# RA6M2 register map
Vendor: Renesas Electronics Corporation; Series: RA6; File version: 1.1
CPU: CM4 r0p1, little endian, MPU, FPU, VTOR, 4 interrupt priority bits
Registers are 8-bit, read-write, reset 0x0 unless marked. A register's access mark holds for its fields unless they carry their own. Offsets are from the block's base; [hi:lo] are bit positions; {n}, {i} and the like mark numbered series; 'fields as' and 'values as' point back to an identical list.

## GPT32EH0 (part 1 of 2) — General PWM Timer 0 (32-bit Enhanced High Resolution)
Base 0x40078000
Same registers: GPT32EH1 0x40078100, GPT32EH2 0x40078200, GPT32EH3 0x40078300, GPT32E4 0x40078400, GPT32E5 0x40078500, GPT32E6 0x40078600, GPT32E7 0x40078700
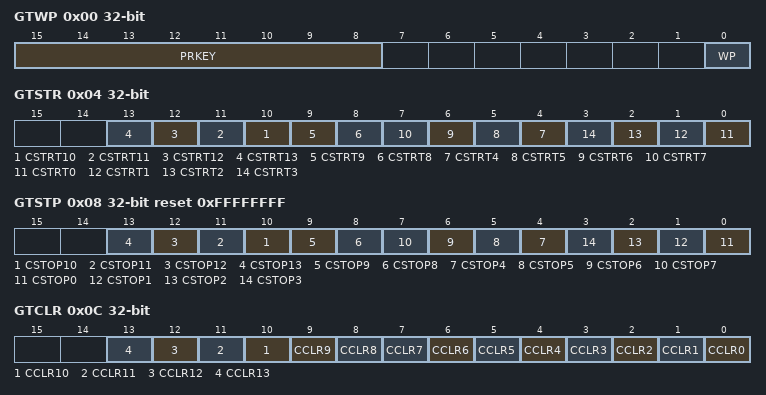
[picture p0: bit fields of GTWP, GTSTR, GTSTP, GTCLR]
0x00 GTWP 32-bit — General PWM Timer Write-Protection Register
  [15:8] PRKEY wo — GTWP Key Code
    165=Written to these bits, the WP bits write is permitted; other=others (The WP bits write is not permitted.)
  [0] WP — Register Write Disable
    0=Enable writes to the register; 1=Disable writes to the register
0x04 GTSTR 32-bit — General PWM Timer Software Start Register
  [n] CSTRT{n} (n=10..13) — Channel {n} GTCNT Count StartRead data shows each channel's counter status (GTCR.CST bit). 0 means counter stop. 1 means counter running.
    0=No effect (write) / counter stop (read); 1=GPT{n+3200}.GTCNT counter starts (write) / Counter running (read)
  [9] CSTRT9 — Channel 9 GTCNT Count StartRead data shows each channel's counter status (GTCR.CST bit). 0 means counter stop. 1 means counter running.
    0=No effect (write) / counter stop (read); 1=GPT329.GTCNT counter starts (write) / Counter running (read)
  [8] CSTRT8 — Channel 8 GTCNT Count StartRead data shows each channel's counter status (GTCR.CST bit). 0 means counter stop. 1 means counter running.
    0=No effect (write) / counter stop (read); 1=GPT328.GTCNT counter starts (write) / Counter running (read)
  [n] CSTRT{n} (n=4..7) — Channel {n} GTCNT Count StartRead data shows each channel's counter status (GTCR.CST bit). 0 means counter stop. 1 means counter running.
    0=No effect (write) / counter stop (read); 1=GPT32E{n}.GTCNT counter starts (write) / Counter running (read)
  [n] CSTRT{n} (n=0..3) — Channel {n} GTCNT Count StartRead data shows each channel's counter status (GTCR.CST bit). 0 means counter stop. 1 means counter running.
    0=No effect (write) / counter stop (read); 1=GPT32EH{n}.GTCNT counter starts (write) / Counter running (read)
0x08 GTSTP 32-bit reset 0xFFFFFFFF — General PWM Timer Software Stop Register
  [n] CSTOP{n} (n=10..13) — Channel {n} GTCNT Count StopRead data shows each channel's counter status (GTCR.CST bit). 0 means counter runnning. 1 means counter stop.
    0=No effect (write) / counter running (read); 1=GPT{n+3200}.GTCNT counter stops (write) / Counter stop (read)
  [9] CSTOP9 — Channel 9 GTCNT Count StopRead data shows each channel's counter status (GTCR.CST bit). 0 means counter runnning. 1 means counter stop.
    0=No effect (write) / counter running (read); 1=GPT329.GTCNT counter stops (write) / Counter stop (read)
  [8] CSTOP8 — Channel 8 GTCNT Count StopRead data shows each channel's counter status (GTCR.CST bit). 0 means counter runnning. 1 means counter stop.
    0=No effect (write) / counter running (read); 1=GPT328.GTCNT counter stops (write) / Counter stop (read)
  [n] CSTOP{n} (n=4..7) — Channel {n} GTCNT Count StopRead data shows each channel's counter status (GTCR.CST bit). 0 means counter runnning. 1 means counter stop.
    0=No effect (write) / counter running (read); 1=GPT32E{n}.GTCNT counter stops (write) / Counter stop (read)
  [n] CSTOP{n} (n=0..3) — Channel {n} GTCNT Count StopRead data shows each channel's counter status (GTCR.CST bit). 0 means counter runnning. 1 means counter stop.
    0=No effect (write) / counter running (read); 1=GPT32EH{n}.GTCNT counter stops (write) / Counter stop (read)
0x0C GTCLR 32-bit wo — General PWM Timer Software Clear Register
  [n] CCLR{n} (n=10..13) — Channel {n} GTCNT Count Clear
    0=No effect; 1=GPT{n+3200}.GTCNT counter clears
  [9] CCLR9 — Channel 9 GTCNT Count Clear
    0=No effect; 1=GPT329.GTCNT counter clears
  [8] CCLR8 — Channel 8 GTCNT Count Clear
    0=No effect; 1=GPT328.GTCNT counter clears
  [n] CCLR{n} (n=4..7) — Channel {n} GTCNT Count Clear
    0=No effect; 1=GPT32E{n}.GTCNT counter clears
  [n] CCLR{n} (n=0..3) — Channel {n} GTCNT Count Clear
    0=No effect; 1=GPT32EH{n}.GTCNT counter clears
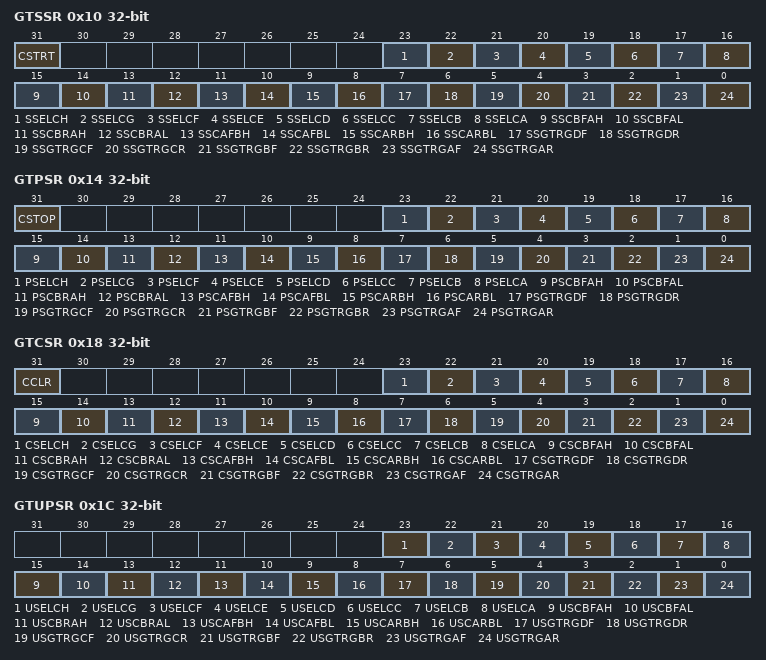
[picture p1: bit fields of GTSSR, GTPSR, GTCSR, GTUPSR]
0x10 GTSSR 32-bit — General PWM Timer Start Source Select Register
  [31] CSTRT — Software Source Counter Start Enable
    0=Disable counter start by the GTSTR register; 1=Enable counter start by the GTSTR register
  [23] SSELCH — ELC_GPTH Event Source Counter Start Enable
    0=Disable counter start on ELC_GPTH input; 1=Enable counter start on ELC_GPTH input
  [22] SSELCG — ELC_GPTG Event Source Counter Start Enable
    0=Disable counter start on ELC_GPTG input; 1=Enable counter start on ELC_GPTG input
  [21] SSELCF — ELC_GPTF Event Source Counter Start Enable
    0=Disable counter start on ELC_GPTF input; 1=Enable counter start on ELC_GPTF input
  [20] SSELCE — ELC_GPTE Event Source Counter Start Enable
    0=Disable counter start on ELC_GPTE input; 1=Enable counter start on ELC_GPTE input
  [19] SSELCD — ELC_GPTD Event Source Counter Start Enable
    0=Disable counter start on ELC_GPTD input; 1=Enable counter start on ELC_GPTD input
  [18] SSELCC — ELC_GPTC Event Source Counter Start Enable
    0=Disable counter start on ELC_GPTC input; 1=Enable counter start on ELC_GPTC input
  [17] SSELCB — ELC_GPTB Event Source Counter Start Enable
    0=Disable counter start on ELC_GPTB input; 1=Enable counter start on ELC_GPTB input
  [16] SSELCA — ELC_GPTA Event Source Counter Start Enable
    0=Disable counter start on ELC_GPTA input; 1=Enable counter start on ELC_GPTA input
  [15] SSCBFAH — GTIOCB Pin Falling Input during GTIOCA Value High Source Counter Start Enable
    0=Disable counter start on the falling edge of GTIOCB input when GTIOCA input is 1; 1=Enable counter start on the falling edge of GTIOCB input when GTIOCA input is 1
  [14] SSCBFAL — GTIOCB Pin Falling Input during GTIOCA Value Low Source Counter Start Enable
    0=Disable counter start on the falling edge of GTIOCB input when GTIOCA input is 0; 1=Enable counter start on the falling edge of GTIOCB input when GTIOCA input is 0
  [13] SSCBRAH — GTIOCB Pin Rising Input during GTIOCA Value High Source Counter Start Enable
    0=Disable counter start on the rising edge of GTIOCB input when GTIOCA input is 1; 1=Enable counter start on the rising edge of GTIOCB input when GTIOCA input is 1
  [12] SSCBRAL — GTIOCB Pin Rising Input during GTIOCA Value Low Source Counter Start Enable
    0=Disable counter start on the rising edge of GTIOCB input when GTIOCA input is 0; 1=Enable counter start on the rising edge of GTIOCB input when GTIOCA input is 0
  [11] SSCAFBH — GTIOCA Pin Falling Input during GTIOCB Value High Source Counter Start Enable
    0=Disable counter start on the falling edge of GTIOCA input when GTIOCB input is 1; 1=Enable counter start on the falling edge of GTIOCA input when GTIOCB input is 1
  [10] SSCAFBL — GTIOCA Pin Falling Input during GTIOCB Value Low Source Counter Start Enable
    0=Disable counter start on the falling edge of GTIOCA input when GTIOCB input is 0; 1=Enable counter start on the falling edge of GTIOCA input when GTIOCB input is 0
  [9] SSCARBH — GTIOCA Pin Rising Input during GTIOCB Value High Source Counter Start Enable
    0=Disable counter start on the rising edge of GTIOCA input when GTIOCB input is 1; 1=Enable counter start on the rising edge of GTIOCA input when GTIOCB input is 1
  [8] SSCARBL — GTIOCA Pin Rising Input during GTIOCB Value Low Source Counter Start Enable
    0=Disable counter start on the rising edge of GTIOCA input when GTIOCB input is 0; 1=Enable counter start on the rising edge of GTIOCA input when GTIOCB input is 0
  [7] SSGTRGDF — GTETRGD Pin Falling Input Source Counter Start Enable
    0=Disable counter start on the falling edge of GTETRGD input; 1=Enable counter start on the falling edge of GTETRGD input
  [6] SSGTRGDR — GTETRGD Pin Rising Input Source Counter Start Enable
    0=Disable counter start on the rising edge of GTETRGD input; 1=Enable counter start on the rising edge of GTETRGD input
  [5] SSGTRGCF — GTETRGC Pin Falling Input Source Counter Start Enable
    0=Disable counter start on the falling edge of GTETRGC input; 1=Enable counter start on the falling edge of GTETRGC input
  [4] SSGTRGCR — GTETRGC Pin Rising Input Source Counter Start Enable
    0=Disable counter start on the rising edge of GTETRGC input; 1=Enable counter start on the rising edge of GTETRGC input
  [3] SSGTRGBF — GTETRGB Pin Falling Input Source Counter Start Enable
    0=Disable counter start on the falling edge of GTETRGB input; 1=Enable counter start on the falling edge of GTETRGB input
  [2] SSGTRGBR — GTETRGB Pin Rising Input Source Counter Start Enable
    0=Disable counter start on the rising edge of GTETRGB input; 1=Enable counter start on the rising edge of GTETRGB input
  [1] SSGTRGAF — GTETRGA Pin Falling Input Source Counter Start Enable
    0=Disable counter start on the falling edge of GTETRGA input; 1=Enable counter start on the falling edge of GTETRGA input
  [0] SSGTRGAR — GTETRGA Pin Rising Input Source Counter Start Enable
    0=Disable counter start on the rising edge of GTETRGA input; 1=Enable counter start on the rising edge of GTETRGA input
0x14 GTPSR 32-bit — General PWM Timer Stop Source Select Register
  [31] CSTOP — Software Source Counter Stop Enable
    0=Disable counter stop by the GTSTP register; 1=Enable counter stop by the GTSTP register
  [23] PSELCH — ELC_GPTH Event Source Counter Stop Enable
    0=Disable counter stop on ELC_GPTH input; 1=Enable counter stop on ELC_GPTH input
  [22] PSELCG — ELC_GPTG Event Source Counter Stop Enable
    0=Disable counter stop on ELC_GPTG input; 1=Enable counter stop on ELC_GPTG input
  [21] PSELCF — ELC_GPTF Event Source Counter Stop Enable
    0=Disable counter stop on ELC_GPTF input; 1=Enable counter stop on ELC_GPTF input
  [20] PSELCE — ELC_GPTE Event Source Counter Stop Enable
    0=Disable counter stop on ELC_GPTE input; 1=Enable counter stop on ELC_GPTE input
  [19] PSELCD — ELC_GPTD Event Source Counter Stop Enable
    0=Disable counter stop on ELC_GPTD input; 1=Enable counter stop on ELC_GPTD input
  [18] PSELCC — ELC_GPTC Event Source Counter Stop Enable
    0=Disable counter stop on ELC_GPTC input; 1=Enable counter stop on ELC_GPTC input
  [17] PSELCB — ELC_GPTB Event Source Counter Stop Enable
    0=Disable counter stop on ELC_GPTB input; 1=Enable counter stop on ELC_GPTB input
  [16] PSELCA — ELC_GPTA Event Source Counter Stop Enable
    0=Disable counter stop on ELC_GPTA input; 1=Enable counter stop on ELC_GPTA input
  [15] PSCBFAH — GTIOCB Pin Falling Input during GTIOCA Value High Source Counter Stop Enable
    0=Disable counter stop on the falling edge of GTIOCB input when GTIOCA input is 1; 1=Enable counter stop on the falling edge of GTIOCB input when GTIOCA input is 1
  [14] PSCBFAL — GTIOCB Pin Falling Input during GTIOCA Value Low Source Counter Stop Enable
    0=Disable counter stop on the falling edge of GTIOCB input when GTIOCA input is 0; 1=Enable counter stop on the falling edge of GTIOCB input when GTIOCA input is 0
  [13] PSCBRAH — GTIOCB Pin Rising Input during GTIOCA Value High Source Counter Stop Enable
    0=Disable counter stop on the rising edge of GTIOCB input when GTIOCA input is 1; 1=Enable counter stop on the rising edge of GTIOCB input when GTIOCA input is 1
  [12] PSCBRAL — GTIOCB Pin Rising Input during GTIOCA Value Low Source Counter Stop Enable
    0=Disable counter stop on the rising edge of GTIOCB input when GTIOCA input is 0; 1=Enable counter stop on the rising edge of GTIOCB input when GTIOCA input is 0
  [11] PSCAFBH — GTIOCA Pin Falling Input during GTIOCB Value High Source Counter Stop Enable
    0=Disable counter stop on the falling edge of GTIOCA input when GTIOCB input is 1; 1=Enable counter stop on the falling edge of GTIOCA input when GTIOCB input is 1
  [10] PSCAFBL — GTIOCA Pin Falling Input during GTIOCB Value Low Source Counter Stop Enable
    0=Disable counter stop on the falling edge of GTIOCA input when GTIOCB input is 0; 1=Enable counter stop on the falling edge of GTIOCA input when GTIOCB input is 0
  [9] PSCARBH — GTIOCA Pin Rising Input during GTIOCB Value High Source Counter Stop Enable
    0=Disable counter stop on the rising edge of GTIOCA input when GTIOCB input is 1; 1=Enable counter stop on the rising edge of GTIOCA input when GTIOCB input is 1
  [8] PSCARBL — GTIOCA Pin Rising Input during GTIOCB Value Low Source Counter Stop Enable
    0=Disable counter stop on the rising edge of GTIOCA input when GTIOCB input is 0; 1=Enable counter stop on the rising edge of GTIOCA input when GTIOCB input is 0
  [7] PSGTRGDF — GTETRGD Pin Falling Input Source Counter Stop Enable
    0=Disable counter stop on the falling edge of GTETRGD input; 1=Enable counter stop on the falling edge of GTETRGD input
  [6] PSGTRGDR — GTETRGD Pin Rising Input Source Counter Stop Enable
    0=Disable counter stop on the rising edge of GTETRGD input; 1=Enable counter stop on the rising edge of GTETRGD input
  [5] PSGTRGCF — GTETRGC Pin Falling Input Source Counter Stop Enable
    0=Disable counter stop on the falling edge of GTETRGC input; 1=Enable counter stop on the falling edge of GTETRGC input
  [4] PSGTRGCR — GTETRGC Pin Rising Input Source Counter Stop Enable
    0=Disable counter stop on the rising edge of GTETRGC input; 1=Enable counter stop on the rising edge of GTETRGC input
  [3] PSGTRGBF — GTETRGB Pin Falling Input Source Counter Stop Enable
    0=Disable counter stop on the falling edge of GTETRGB input; 1=Enable counter stop on the falling edge of GTETRGB input
  [2] PSGTRGBR — GTETRGB Pin Rising Input Source Counter Stop Enable
    0=Disable counter stop on the rising edge of GTETRGB input; 1=Enable counter stop on the rising edge of GTETRGB input
  [1] PSGTRGAF — GTETRGA Pin Falling Input Source Counter Stop Enable
    0=Disable counter stop on the falling edge of GTETRGA input; 1=Enable counter stop on the falling edge of GTETRGA input
  [0] PSGTRGAR — GTETRGA Pin Rising Input Source Counter Stop Enable
    0=Disable counter stop on the rising edge of GTETRGA input; 1=Enable counter stop on the rising edge of GTETRGA input
0x18 GTCSR 32-bit — General PWM Timer Clear Source Select Register
  [31] CCLR — Software Source Counter Clear Enable
    0=Disable counter clear by the GTCLR register; 1=Enable counter clear by the GTCLR register
  [23] CSELCH — ELC_GPTH Event Source Counter Clear Enable
    0=Disable counter clear on ELC_GPTH input; 1=Enable counter clear on ELC_GPTH input
  [22] CSELCG — ELC_GPTG Event Source Counter Clear Enable
    0=Disable counter clear on ELC_GPTG input; 1=Enable counter clear on ELC_GPTG input
  [21] CSELCF — ELC_GPTF Event Source Counter Clear Enable
    0=Disable counter clear on ELC_GPTF input; 1=Enable counter clear on ELC_GPTF input
  [20] CSELCE — ELC_GPTE Event Source Counter Clear Enable
    0=Disable counter clear on ELC_GPTE input; 1=Enable counter clear on ELC_GPTE input
  [19] CSELCD — ELC_GPTD Event Source Counter Clear Enable
    0=Disable counter clear on ELC_GPTD input; 1=Enable counter clear on ELC_GPTD input
  [18] CSELCC — ELC_GPTC Event Source Counter Clear Enable
    0=Disable counter clear on ELC_GPTC input; 1=Enable counter clear on ELC_GPTC input
  [17] CSELCB — ELC_GPTB Event Source Counter Clear Enable
    0=Disable counter clear on ELC_GPTB input; 1=Enable counter clear on ELC_GPTB input
  [16] CSELCA — ELC_GPTA Event Source Counter Clear Enable
    0=Disable counter clear on ELC_GPTA input; 1=Enable counter clear on ELC_GPTA input
  [15] CSCBFAH — GTIOCB Pin Falling Input during GTIOCA Value High Source Counter Clear Enable
    0=Disable counter clear on the falling edge of GTIOCB input when GTIOCA input is 1; 1=Enable counter clear on the falling edge of GTIOCB input when GTIOCA input is 1
  [14] CSCBFAL — GTIOCB Pin Falling Input during GTIOCA Value Low Source Counter Clear Enable
    0=Disable counter clear on the falling edge of GTIOCB input when GTIOCA input is 0; 1=Enable counter clear on the falling edge of GTIOCB input when GTIOCA input is 0
  [13] CSCBRAH — GTIOCB Pin Rising Input during GTIOCA Value High Source Counter Clear Enable
    0=Disable counter clear on the rising edge of GTIOCB input when GTIOCA input is 1; 1=Enable counter clear on the rising edge of GTIOCB input when GTIOCA input is 1
  [12] CSCBRAL — GTIOCB Pin Rising Input during GTIOCA Value Low Source Counter Clear Enable
    0=Disable counter clear on the rising edge of GTIOCB input when GTIOCA input is 0; 1=Enable counter clear on the rising edge of GTIOCB input when GTIOCA input is 0
  [11] CSCAFBH — GTIOCA Pin Falling Input during GTIOCB Value High Source Counter Clear Enable
    0=Disable counter clear on the falling edge of GTIOCA input when GTIOCB input is 1; 1=Enable counter clear on the falling edge of GTIOCA input when GTIOCB input is 1
  [10] CSCAFBL — GTIOCA Pin Falling Input during GTIOCB Value Low Source Counter Clear Enable
    0=Disable counter clear on the falling edge of GTIOCA input when GTIOCB input is 0; 1=Enable counter clear on the falling edge of GTIOCA input when GTIOCB input is 0
  [9] CSCARBH — GTIOCA Pin Rising Input during GTIOCB Value High Source Counter Clear Enable
    0=Disable counter clear on the rising edge of GTIOCA input when GTIOCB input is 1; 1=Enable counter clear on the rising edge of GTIOCA input when GTIOCB input is 1
  [8] CSCARBL — GTIOCA Pin Rising Input during GTIOCB Value Low Source Counter Clear Enable
    0=Disable counter clear on the rising edge of GTIOCA input when GTIOCB input is 0; 1=Enable counter clear on the rising edge of GTIOCA input when GTIOCB input is 0
  [7] CSGTRGDF — GTETRGD Pin Falling Input Source Counter Clear Enable
    0=Disable counter clear on the falling edge of GTETRGD input; 1=Enable counter clear on the falling edge of GTETRGD input
  [6] CSGTRGDR — GTETRGD Pin Rising Input Source Counter Clear Enable
    0=Disable counter clear on the rising edge of GTETRGD input; 1=Enable counter clear on the rising edge of GTETRGD input
  [5] CSGTRGCF — GTETRGC Pin Falling Input Source Counter Clear Enable
    0=Disable counter clear on the falling edge of GTETRGC input; 1=Enable counter clear on the falling edge of GTETRGC input
  [4] CSGTRGCR — GTETRGC Pin Rising Input Source Counter Clear Enable
    0=Disable counter clear on the rising edge of GTETRGC input; 1=Enable counter clear on the rising edge of GTETRGC input
  [3] CSGTRGBF — GTETRGB Pin Falling Input Source Counter Clear Enable
    0=Disable counter clear on the falling edge of GTETRGB input; 1=Enable counter clear on the falling edge of GTETRGB input
  [2] CSGTRGBR — GTETRGB Pin Rising Input Source Counter Clear Enable
    0=Disable counter clear on the rising edge of GTETRGB input; 1=Enable counter clear on the rising edge of GTETRGB input
  [1] CSGTRGAF — GTETRGA Pin Falling Input Source Counter Clear Enable
    0=Disable counter clear on the falling edge of GTETRGA input; 1=Enable counter clear on the falling edge of GTETRGA input
  [0] CSGTRGAR — GTETRGA Pin Rising Input Source Counter Clear Enable
    0=Disable counter clear on the rising edge of GTETRGA input; 1=Enable counter clear on the rising edge of GTETRGA input
0x1C GTUPSR 32-bit — General PWM Timer Up Count Source Select Register
  [23] USELCH — ELC_GPTH Event Source Counter Count Up Enable
    0=Disable counter count up on ELC_GPTH input; 1=Enable counter count up on ELC_GPTH input
  [22] USELCG — ELC_GPTG Event Source Counter Count Up Enable
    0=Disable counter count up on ELC_GPTG input; 1=Enable counter count up on ELC_GPTG input
  [21] USELCF — ELC_GPTF Event Source Counter Count Up Enable
    0=Disable counter count up on ELC_GPTF input; 1=Enable counter count up on ELC_GPTF input
  [20] USELCE — ELC_GPTE Event Source Counter Count Up Enable
    0=Disable counter count up on ELC_GPTE input; 1=Enable counter count up on ELC_GPTE input.put
  [19] USELCD — ELC_GPTD Event Source Counter Count Up Enable
    0=Disable counter count up on ELC_GPTD input; 1=Enable counter count up on ELC_GPTD input
  [18] USELCC — ELC_GPTC Event Source Counter Count Up Enable
    0=Disable counter count up on ELC_GPTC input; 1=Enable counter count up on ELC_GPTC input
  [17] USELCB — ELC_GPTB Event Source Counter Count Up Enable
    0=Disable counter count up on ELC_GPTB input; 1=Enable counter count up on ELC_GPTB input
  [16] USELCA — ELC_GPTA Event Source Counter Count Up Enable
    0=Disable counter count up on ELC_GPTA input; 1=Enable counter count up on ELC_GPTA input
  [15] USCBFAH — GTIOCB Pin Falling Input during GTIOCA Value High Source Counter Count Up Enable
    0=Disable counter count up on the falling edge of GTIOCB input when GTIOCA input is 1; 1=Enable counter count up on the falling edge of GTIOCB input when GTIOCA input is 1
  [14] USCBFAL — GTIOCB Pin Falling Input during GTIOCA Value Low Source Counter Count Up Enable
    0=Disable counter count up on the falling edge of GTIOCB input when GTIOCA input is 0; 1=Enable counter count up on the falling edge of GTIOCB input when GTIOCA input is 0
  [13] USCBRAH — GTIOCB Pin Rising Input during GTIOCA Value High Source Counter Count Up Enable
    0=Disable counter count up on the rising edge of GTIOCB input when GTIOCA input is 1; 1=Enable counter count up on the rising edge of GTIOCB input when GTIOCA input is 1
  [12] USCBRAL — GTIOCB Pin Rising Input during GTIOCA Value Low Source Counter Count Up Enable
    0=Disable counter count up on the rising edge of GTIOCB input when GTIOCA input is 0; 1=Enable counter count up on the rising edge of GTIOCB input when GTIOCA input is 0
  [11] USCAFBH — GTIOCA Pin Falling Input during GTIOCB Value High Source Counter Count Up Enable
    0=Disable counter count up on the falling edge of GTIOCA input when GTIOCB input is 1; 1=Enable counter count up on the falling edge of GTIOCA input when GTIOCB input is 1
  [10] USCAFBL — GTIOCA Pin Falling Input during GTIOCB Value Low Source Counter Count Up Enable
    0=Disable counter count up on the falling edge of GTIOCA input when GTIOCB input is 0; 1=Enable counter count up on the falling edge of GTIOCA input when GTIOCB input is 0
  [9] USCARBH — GTIOCA Pin Rising Input during GTIOCB Value High Source Counter Count Up Enable
    0=Disable counter count up on the rising edge of GTIOCA input when GTIOCB input is 1; 1=Enable counter count up on the rising edge of GTIOCA input when GTIOCB input is 1
  [8] USCARBL — GTIOCA Pin Rising Input during GTIOCB Value Low Source Counter Count Up Enable
    0=Disable counter count up on the rising edge of GTIOCA input when GTIOCB input is 0; 1=Enable counter count up on the rising edge of GTIOCA input when GTIOCB input is 0
  [7] USGTRGDF — GTETRGD Pin Falling Input Source Counter Count Up Enable
    0=Disable counter count up on the falling edge of GTETRGD input; 1=Enable counter count up on the falling edge of GTETRGD input
  [6] USGTRGDR — GTETRGD Pin Rising Input Source Counter Count Up Enable
    0=Disable counter count up on the rising edge of GTETRGD input; 1=Enable counter count up on the rising edge of GTETRGD input
  [5] USGTRGCF — GTETRGC Pin Falling Input Source Counter Count Up Enable
    0=Disable counter count up on the falling edge of GTETRGC input; 1=Enable counter count up on the falling edge of GTETRGC input
  [4] USGTRGCR — GTETRGC Pin Rising Input Source Counter Count Up Enable
    0=Disable counter count up on the rising edge of GTETRGC input; 1=Enable counter count up on the rising edge of GTETRGC input
  [3] USGTRGBF — GTETRGB Pin Falling Input Source Counter Count Up Enable
    0=Disable counter count up on the falling edge of GTETRGB input; 1=Enable counter count up on the falling edge of GTETRGB input
  [2] USGTRGBR — GTETRGB Pin Rising Input Source Counter Count Up Enable
    0=Disable counter count up on the rising edge of GTETRGB input; 1=Enable counter count up on the rising edge of GTETRGB input
  [1] USGTRGAF — GTETRGA Pin Falling Input Source Counter Count Up Enable
    0=Disable counter count up on the falling edge of GTETRGA input; 1=Enable counter count up on the falling edge of GTETRGA input
  [0] USGTRGAR — GTETRGA Pin Rising Input Source Counter Count Up Enable
    0=Disable counter count up on the rising edge of GTETRGA input; 1=Enable counter count up on the rising edge of GTETRGA input
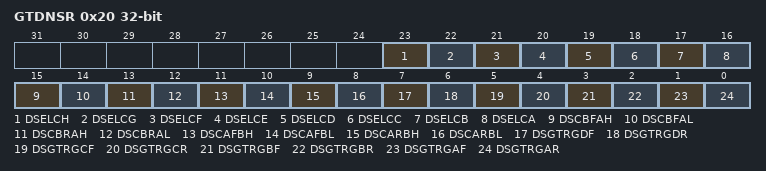
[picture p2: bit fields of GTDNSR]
0x20 GTDNSR 32-bit — General PWM Timer Down Count Source Select Register
  [23] DSELCH — ELC_GPTH Event Source Counter Count Down Enable
    0=Disable counter count down on ELC_GPTH input; 1=Enable counter count down on ELC_GPTH input
  [22] DSELCG — ELC_GPTG Event Source Counter Count Down Enable
    0=Disable counter count down on ELC_GPTG input; 1=Enable counter count down on ELC_GPTG input
  [21] DSELCF — ELC_GPTF Event Source Counter Count Down Enable
    0=Disable counter count down on ELC_GPTF input; 1=Enable counter count down on ELC_GPTF input
  [20] DSELCE — ELC_GPTE Event Source Counter Count Down Enable
    0=Disable counter count down on ELC_GPTE input; 1=Enable counter count down on ELC_GPTE input
  [19] DSELCD — ELC_GPTD Event Source Counter Count Down Enable
    0=Disable counter count down on ELC_GPTD input; 1=Enable counter count down on ELC_GPTD input
  [18] DSELCC — ELC_GPTC Event Source Counter Count Down Enable
    0=Disable counter count down on ELC_GPTC input; 1=Enable counter count down on ELC_GPTC input
  [17] DSELCB — ELC_GPTB Event Source Counter Count Down Enable
    0=Disable counter count down on ELC_GPTB input; 1=Enable counter count down on ELC_GPTB input
  [16] DSELCA — ELC_GPTA Event Source Counter Count Down Enable
    0=Disable counter count down on ELC_GPTA input; 1=Enable counter count down on ELC_GPTA input
  [15] DSCBFAH — GTIOCB Pin Falling Input during GTIOCA Value High Source Counter Count Down Enable
    0=Disable counter count down on the falling edge of GTIOCB input when GTIOCA input is 1; 1=Enable counter count down on the falling edge of GTIOCB input when GTIOCA input is 1
  [14] DSCBFAL — GTIOCB Pin Falling Input during GTIOCA Value Low Source Counter Count Down Enable
    0=Disable counter count down on the falling edge of GTIOCB input when GTIOCA input is 0; 1=Enable counter count down on the falling edge of GTIOCB input when GTIOCA input is 0
  [13] DSCBRAH — GTIOCB Pin Rising Input during GTIOCA Value High Source Counter Count Down Enable
    0=Disable counter count down on the rising edge of GTIOCB input when GTIOCA input is 1; 1=Enable counter count down on the rising edge of GTIOCB input when GTIOCA input is 1
  [12] DSCBRAL — GTIOCB Pin Rising Input during GTIOCA Value Low Source Counter Count Down Enable
    0=Disable counter count down on the rising edge of GTIOCB input when GTIOCA input is 0; 1=Enable counter count down on the rising edge of GTIOCB input when GTIOCA input is 0
  [11] DSCAFBH — GTIOCA Pin Falling Input during GTIOCB Value High Source Counter Count Down Enable
    0=Disable counter count down on the falling edge of GTIOCA input when GTIOCB input is 1; 1=Enable counter count down on the falling edge of GTIOCA input when GTIOCB input is 1
  [10] DSCAFBL — GTIOCA Pin Falling Input during GTIOCB Value Low Source Counter Count Down Enable
    0=Disable counter count down on the falling edge of GTIOCA input when GTIOCB input is 0; 1=Enable counter count down on the falling edge of GTIOCA input when GTIOCB input is 0
  [9] DSCARBH — GTIOCA Pin Rising Input during GTIOCB Value High Source Counter Count Down Enable
    0=Disable counter count down on the rising edge of GTIOCA input when GTIOCB input is 1; 1=Enable counter count down on the rising edge of GTIOCA input when GTIOCB input is 1
  [8] DSCARBL — GTIOCA Pin Rising Input during GTIOCB Value Low Source Counter Count Down Enable
    0=Disable counter count down on the rising edge of GTIOCA input when GTIOCB input is 0; 1=Enable counter count down on the rising edge of GTIOCA input when GTIOCB input is 0
  [7] DSGTRGDF — GTETRGD Pin Falling Input Source Counter Count Down Enable
    0=Disable counter count down on the falling edge of GTETRGD input; 1=Enable counter count down on the falling edge of GTETRGD input
  [6] DSGTRGDR — GTETRGD Pin Rising Input Source Counter Count Down Enable
    0=Disable counter count down on the rising edge of GTETRGD input; 1=Enable counter count down on the rising edge of GTETRGD input
  [5] DSGTRGCF — GTETRGC Pin Falling Input Source Counter Count Down Enable
    0=Disable counter count down on the falling edge of GTETRGC input; 1=Enable counter count down on the falling edge of GTETRGC input
  [4] DSGTRGCR — GTETRGC Pin Rising Input Source Counter Count Down Enable
    0=Disable counter count down on the rising edge of GTETRGC input; 1=Enable counter count down on the rising edge of GTETRGC input
  [3] DSGTRGBF — GTETRGB Pin Falling Input Source Counter Count Down Enable
    0=Disable counter count down on the falling edge of GTETRGB input; 1=Enable counter count down on the falling edge of GTETRGB input
  [2] DSGTRGBR — GTETRGB Pin Rising Input Source Counter Count Down Enable
    0=Disable counter count down on the rising edge of GTETRGB input; 1=Enable counter count down on the rising edge of GTETRGB input
  [1] DSGTRGAF — GTETRGA Pin Falling Input Source Counter Count Down Enable
    0=Disable counter count down on the falling edge of GTETRGA input; 1=Enable counter count down on the falling edge of GTETRGA input
  [0] DSGTRGAR — GTETRGA Pin Rising Input Source Counter Count Down Enable
    0=Disable counter count down on the rising edge of GTETRGA input; 1=Enable counter count down on the rising edge of GTETRGA input

## GPT328 (part 1 of 2) — General PWM Timer 8 (32-bit Enhanced)
Base 0x40078800
Same registers: GPT329 0x40078900, GPT3210 0x40078A00, GPT3211 0x40078B00, GPT3212 0x40078C00, GPT3213 0x40078D00
Registers as GPT32EH0; these are added or differ:
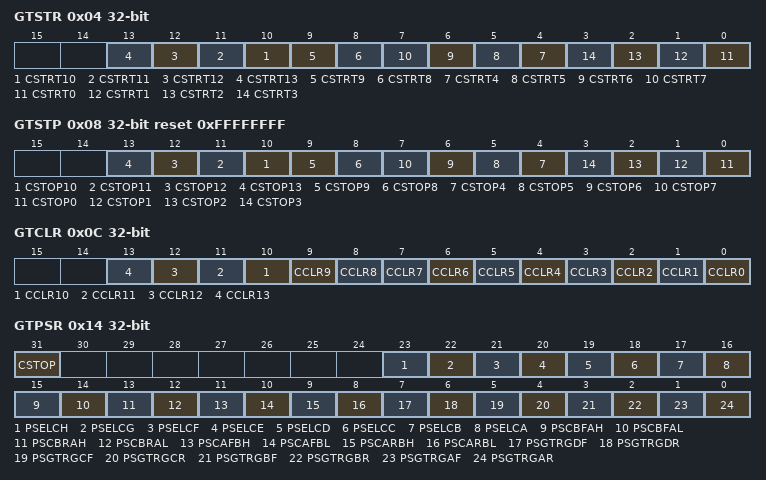
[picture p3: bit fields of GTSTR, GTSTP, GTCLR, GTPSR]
0x04 GTSTR 32-bit — General PWM Timer Software Start Register
  fields as GPT32EH0.GTSTR
0x08 GTSTP 32-bit reset 0xFFFFFFFF — General PWM Timer Software Stop Register
  fields as GPT32EH0.GTSTP
0x0C GTCLR 32-bit wo — General PWM Timer Software Clear Register
  fields as GPT32EH0.GTCLR
0x14 GTPSR 32-bit — General PWM Timer Stop Source Select Register
  [31] CSTOP — Software Source Counter Stop Enable
    0=Disable counter stop by the GTSTP register; 1=Enable counter stop by the GTSTP register
  [23] PSELCH — ELC_GPTH Event Source Counter Stop Enable
    0=Disable counter stop on ELC_GPTH input; 1=Enable counter stop on ELCH event inpu
  [22] PSELCG — ELC_GPTG Event Source Counter Stop Enable
    0=Disable counter stop on ELC_GPTG input; 1=Enable counter stop on ELC_GPTG input
  [21] PSELCF — ELC_GPTF Event Source Counter Stop Enable
    0=Disable counter stop on ELC_GPTF input; 1=Enable counter stop on ELC_GPTF input
  [20] PSELCE — ELC_GPTE Event Source Counter Stop Enable
    0=Disable counter stop on ELC_GPTE input; 1=Enable counter stop on ELC_GPTE input
  [19] PSELCD — ELC_GPTD Event Source Counter Stop Enable
    0=Disable counter stop on ELC_GPTD input; 1=Enable counter stop on ELC_GPTD input
  [18] PSELCC — ELC_GPTC Event Source Counter Stop Enable
    0=Disable counter stop on ELC_GPTC input; 1=Enable counter stop on ELC_GPTC input
  [17] PSELCB — ELC_GPTB Event Source Counter Stop Enable
    0=Disable counter stop on ELC_GPTB input; 1=Enable counter stop on ELC_GPTB input
  [16] PSELCA — ELC_GPTA Event Source Counter Stop Enable
    0=Disable counter stop on ELC_GPTA input; 1=Enable counter stop on ELC_GPTA input
  [15] PSCBFAH — GTIOCB Pin Falling Input during GTIOCA Value High Source Counter Stop Enable
    0=Disable counter stop on the falling edge of GTIOCB input when GTIOCA input is 1; 1=Enable counter stop on the falling edge of GTIOCB input when GTIOCA input is 1
  [14] PSCBFAL — GTIOCB Pin Falling Input during GTIOCA Value Low Source Counter Stop Enable
    0=Disable counter stop on the falling edge of GTIOCB input when GTIOCA input is 0; 1=Enable counter stop on the falling edge of GTIOCB input when GTIOCA input is 0
  [13] PSCBRAH — GTIOCB Pin Rising Input during GTIOCA Value High Source Counter Stop Enable
    0=Disable counter stop on the rising edge of GTIOCB input when GTIOCA input is 1; 1=Enable counter stop on the rising edge of GTIOCB input when GTIOCA input is 1
  [12] PSCBRAL — GTIOCB Pin Rising Input during GTIOCA Value Low Source Counter Stop Enable
    0=Disable counter stop on the rising edge of GTIOCB input when GTIOCA input is 0; 1=Enable counter stop on the rising edge of GTIOCB input when GTIOCA input is 0
  [11] PSCAFBH — GTIOCA Pin Falling Input during GTIOCB Value High Source Counter Stop Enable
    0=Disable counter stop on the falling edge of GTIOCA input when GTIOCB input is 1; 1=Enable counter stop on the falling edge of GTIOCA input when GTIOCB input is 1
  [10] PSCAFBL — GTIOCA Pin Falling Input during GTIOCB Value Low Source Counter Stop Enable
    0=Disable counter stop on the falling edge of GTIOCA input when GTIOCB input is 0; 1=Enable counter stop on the falling edge of GTIOCA input when GTIOCB input is 0
  [9] PSCARBH — GTIOCA Pin Rising Input during GTIOCB Value High Source Counter Stop Enable
    0=Disable counter stop on the rising edge of GTIOCA input when GTIOCB input is 1; 1=Enable counter stop on the rising edge of GTIOCA input when GTIOCB input is 1
  [8] PSCARBL — GTIOCA Pin Rising Input during GTIOCB Value Low Source Counter Stop Enable
    0=Disable counter stop on the rising edge of GTIOCA input when GTIOCB input is 0; 1=Enable counter stop on the rising edge of GTIOCA input when GTIOCB input is 0
  [7] PSGTRGDF — GTETRGD Pin Falling Input Source Counter Stop Enable
    0=Disable counter stop on the falling edge of GTETRGD input; 1=Enable counter stop on the falling edge of GTETRGD input
  [6] PSGTRGDR — GTETRGD Pin Rising Input Source Counter Stop Enable
    0=Disable counter stop on the rising edge of GTETRGD input; 1=Enable counter stop on the rising edge of GTETRGD input
  [5] PSGTRGCF — GTETRGC Pin Falling Input Source Counter Stop Enable
    0=Disable counter stop on the falling edge of GTETRGC input; 1=Enable counter stop on the falling edge of GTETRGC input
  [4] PSGTRGCR — GTETRGC Pin Rising Input Source Counter Stop Enable
    0=Disable counter stop on the rising edge of GTETRGC input; 1=Enable counter stop on the rising edge of GTETRGC input
  [3] PSGTRGBF — GTETRGB Pin Falling Input Source Counter Stop Enable
    0=Disable counter stop on the falling edge of GTETRGB input; 1=Enable counter stop on the falling edge of GTETRGB input
  [2] PSGTRGBR — GTETRGB Pin Rising Input Source Counter Stop Enable
    0=Disable counter stop on the rising edge of GTETRGB input; 1=Enable counter stop on the rising edge of GTETRGB input
  [1] PSGTRGAF — GTETRGA Pin Falling Input Source Counter Stop Enable
    0=Disable counter stop on the falling edge of GTETRGA input; 1=Enable counter stop on the falling edge of GTETRGA input
  [0] PSGTRGAR — GTETRGA Pin Rising Input Source Counter Stop Enable
    0=Disable counter stop on the rising edge of GTETRGA input; 1=Enable counter stop on the rising edge of GTETRGA input
